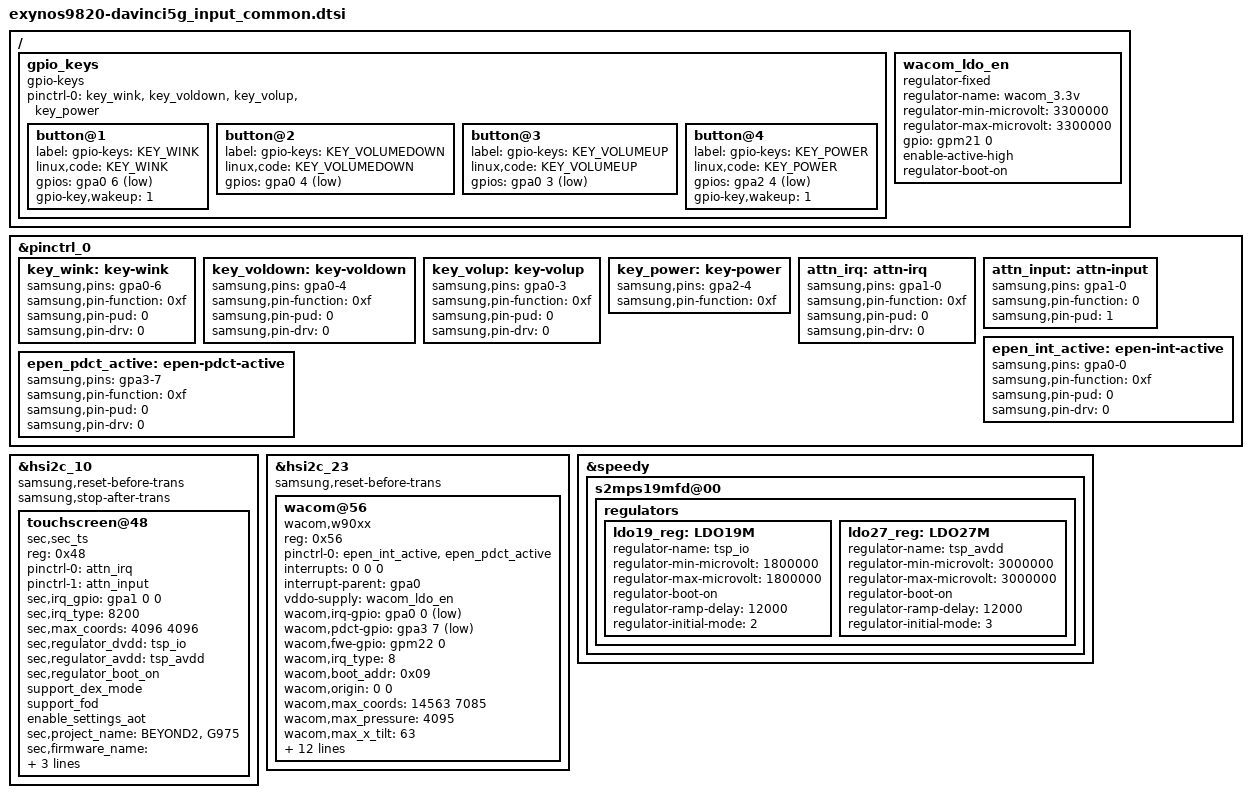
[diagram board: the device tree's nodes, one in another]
/*
 * SAMSUNG EXYNOS9820 board device tree source
 *
 * Copyright (c) 2018 Samsung Electronics Co., Ltd.
 *		http://www.samsung.com
 *
 * This program is free software; you can redistribute it and/or modify
 * it under the terms of the GNU General Public License version 2 as
 * published by the Free Software Foundation.
*/

#include <dt-bindings/input/input.h>

/ {
	fragment@model {
		target-path = "/";
		__overlay__ {
			gpio_keys {
				status = "okay";
				compatible = "gpio-keys";
				pinctrl-names = "default";
				pinctrl-0 = <&key_wink &key_voldown &key_volup &key_power>;
				button@1 {
					label = "gpio-keys: KEY_WINK";
					linux,code = <KEY_WINK>;
					gpios = <&gpa0 6 0xf>;
					gpio-key,wakeup = <1>;
				};
				button@2 {
					label = "gpio-keys: KEY_VOLUMEDOWN";
					linux,code = <KEY_VOLUMEDOWN>;
					gpios = <&gpa0 4 0xf>;
				};
				button@3 {
					label = "gpio-keys: KEY_VOLUMEUP";
					linux,code = <KEY_VOLUMEUP>;
					gpios = <&gpa0 3 0xf>;
				};
				button@4 {
					label = "gpio-keys: KEY_POWER";
					linux,code = <KEY_POWER>;
					gpios = <&gpa2 4 0xf>;
					gpio-key,wakeup = <1>;
				};
			};

			wacom_ldo_en: wacom_ldo_en {
				compatible = "regulator-fixed";
				regulator-name = "wacom_3.3v";
				regulator-min-microvolt = <3300000>;
				regulator-max-microvolt = <3300000>;
				gpio = <&gpm21 0 0>;
				enable-active-high;
				regulator-boot-on;
			};
		};
	};
};

&pinctrl_0 {
	key_wink: key-wink {
		samsung,pins = "gpa0-6";
		samsung,pin-function = <0xf>;
		samsung,pin-pud = <0>;
		samsung,pin-drv = <0>;
	};

	key_voldown: key-voldown {
		samsung,pins = "gpa0-4";
		samsung,pin-function = <0xf>;
		samsung,pin-pud = <0>;
		samsung,pin-drv = <0>;
	};

	key_volup: key-volup {
		samsung,pins = "gpa0-3";
		samsung,pin-function = <0xf>;
		samsung,pin-pud = <0>;
		samsung,pin-drv = <0>;
	};

	key_power: key-power {
		samsung,pins = "gpa2-4";
		samsung,pin-function = <0xf>;
	};

	attn_irq: attn-irq {
		samsung,pins = "gpa1-0";
		samsung,pin-function = <0xf>;
		samsung,pin-pud = <0>;
		samsung,pin-drv = <0>;
	};

	attn_input: attn-input {
		samsung,pins = "gpa1-0";
		samsung,pin-function = <0>;
		samsung,pin-pud = <1>;
	};

	epen_int_active: epen-int-active {
		samsung,pins = "gpa0-0";
		samsung,pin-function = <0xf>;
		samsung,pin-pud = <0>;
		samsung,pin-drv = <0>;
	};

	epen_pdct_active: epen-pdct-active {
		samsung,pins = "gpa3-7";
		samsung,pin-function = <0xf>;
		samsung,pin-pud = <0>;
		samsung,pin-drv = <0>;
	};
};

&hsi2c_10 {
	#address-cells = <1>;
	#size-cells = <0>;
	status = "okay";
	samsung,reset-before-trans;
	samsung,stop-after-trans;	/* LSI IC ONLY */
	touchscreen@48 {
		compatible = "sec,sec_ts";
		reg = <0x48>;
		pinctrl-names = "on_state", "off_state";
		pinctrl-0 = <&attn_irq>;
		pinctrl-1 = <&attn_input>;
		sec,irq_gpio = <&gpa1 0 0>;
		sec,irq_type = <8200>;
		sec,max_coords = <4096 4096>;
//		sec,area-size = <133 266 341>; /* indicator: 24dp navigator:48dp edge:60px dpi=320 */
		sec,regulator_dvdd = "tsp_io";
		sec,regulator_avdd = "tsp_avdd";
		sec,regulator_boot_on;
		support_dex_mode;
		support_fod;
		enable_settings_aot;
		sec,project_name = "BEYOND2", "G975";
		sec,firmware_name = "tsp_sec/y771_beyond2_phole.bin";
		sec,tclm_level = <1>;
//		sec,afe_base = <0x0000>;
		sec,bringup = <2>;
	};
};

&hsi2c_23 {
	status = "okay";
	samsung,reset-before-trans;
	//samsung,transfer_delay = <50>;
	wacom@56 {
		compatible = "wacom,w90xx";
		reg = <0x56>;
		pinctrl-names = "default";
		pinctrl-0 = <&epen_int_active &epen_pdct_active>;
		interrupts = <0 0 0>;
		interrupt-parent = <&gpa0>;
		vddo-supply = <&wacom_ldo_en>;
		/* gpios */
		wacom,irq-gpio = <&gpa0 0 1>;
		wacom,pdct-gpio = <&gpa3 7 1>;
		wacom,fwe-gpio = <&gpm22 0 0>;
		wacom,irq_type = <8>;	/*IRQF_TRIGGER_LOW*/
		/* features */
		wacom,boot_addr = <0x09>;
		wacom,origin = <0 0>; /* x y */
		wacom,max_coords = <14563 7085>; /* x y */
		wacom,max_pressure = <4095>;
		wacom,max_x_tilt = <63>;
		wacom,max_y_tilt = <63>;
		wacom,max_height = <255>;
		wacom,project_name = "DAVINCI", "N970";
		wacom,invert = <1 0 1>; /* x y switch */
		wacom,ic_type = <9020>;
		wacom,fw_path = "epen/w9020_davinci.fw";
		/*wacom,fw_fac_path = "epen/w9018_crown_garage.fw", "epen/w9018_crown_unit.fw";*/
		wacom,use_virtual_softkey;
		wacom,support_aop_mode = "1"; /* S-note want to check to use aop */
		wacom,use_garage;
		wacom,support_dex_mode;
		wacom,dex_rate = <10>;
		wacom,table_swap_for_dex_station;
	};
};

&speedy {
	s2mps19mfd@00 {
		regulators {
			ldo19_reg: LDO19M {
				regulator-name = "tsp_io";
				regulator-min-microvolt = <1800000>;
				regulator-max-microvolt = <1800000>;
				regulator-boot-on;
				regulator-ramp-delay = <12000>;
				regulator-initial-mode = <2>;
			};

			ldo27_reg: LDO27M {
				regulator-name = "tsp_avdd";
				regulator-min-microvolt = <3000000>;
				regulator-max-microvolt = <3000000>;
				regulator-boot-on;
				regulator-ramp-delay = <12000>;
				regulator-initial-mode = <3>;
			};		
		};
	};
};
